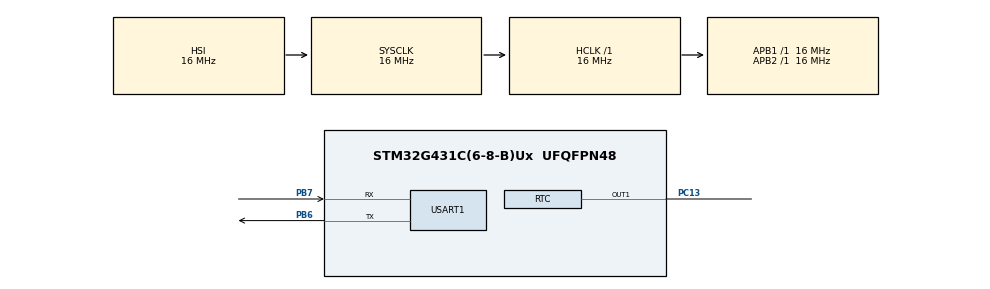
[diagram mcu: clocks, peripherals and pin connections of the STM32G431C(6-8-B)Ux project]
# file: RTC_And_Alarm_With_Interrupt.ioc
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Mcu.Family=STM32G4
Mcu.Name=STM32G431C(6-8-B)Ux
Mcu.Package=UFQFPN48
NVIC.PriorityGroup=NVIC_PRIORITYGROUP_4
NVIC.RTC_Alarm_IRQn=true\:0\:0\:false\:false\:true\:true\:true\:true
NVIC.RTC_WKUP_IRQn=true\:0\:0\:false\:false\:true\:true\:true\:true
PA13.Mode=Serial_Wire
PA13.Signal=SYS_JTMS-SWDIO
PA14.Mode=Serial_Wire
PA14.Signal=SYS_JTCK-SWCLK
PB6.Mode=Asynchronous
PB6.Signal=USART1_TX
PB7.Mode=Asynchronous
PB7.Signal=USART1_RX
PC13.Mode=WakeUpAF1
PC13.Signal=RTC_OUT1
PF0-OSC_IN.Mode=HSE-External-Oscillator
PF0-OSC_IN.Signal=RCC_OSC_IN
PF1-OSC_OUT.Mode=HSE-External-Oscillator
PF1-OSC_OUT.Signal=RCC_OSC_OUT
ProjectManager.HeapSize=0x200
ProjectManager.StackSize=0x400
ProjectManager.TargetToolchain=STM32CubeIDE
RCC.AHBFreq_Value=16000000
RCC.APB1Freq_Value=16000000
RCC.APB1TimFreq_Value=16000000
RCC.APB2Freq_Value=16000000
RCC.APB2TimFreq_Value=16000000
RCC.CortexFreq_Value=16000000
RCC.EXTERNAL_CLOCK_VALUE=12288000
RCC.HCLKFreq_Value=16000000
RCC.HSE_VALUE=8000000
RCC.HSI48_VALUE=48000000
RCC.HSI_VALUE=16000000
RCC.LSE_VALUE=32768
RCC.PLLSourceVirtual=RCC_PLLSOURCE_HSE
RCC.SYSCLKFreq_VALUE=16000000
RCC.USBFreq_Value=32000000
RCC.VCOOutputFreq_Value=64000000
RTC.Alarm-Alarm\ A=RTC_ALARM_A
RTC.AlarmMaskDateWeekDay-Alarm\ A=RTC_ALARMMASK_DATEWEEKDAY
RTC.Date=2
RTC.Format=RTC_FORMAT_BIN
RTC.Hours=10
RTC.Hours_A-Alarm\ A=10
RTC.Minutes=34
RTC.Minutes_A-Alarm\ A=34
RTC.Month=RTC_MONTH_JANUARY
RTC.Seconds_A-Alarm\ A=10
RTC.SynchPrediv=249
RTC.WakeUpClock-WakeUpAF1=RTC_WAKEUPCLOCK_CK_SPRE_16BITS
RTC.WakeUpCounter-WakeUpAF1=5
RTC.WeekDay=RTC_WEEKDAY_MONDAY
RTC.Year=0
USART1.VirtualMode-Asynchronous=VM_ASYNC
VP_RTC_VS_RTC_Activate.Mode=RTC_Enabled
VP_RTC_VS_RTC_Alarm_A_Intern.Mode=Alarm A
VP_RTC_VS_RTC_Calendar.Mode=RTC_Calendar
VP_SYS_VS_DBSignals.Mode=DisableDeadBatterySignals
board=custom

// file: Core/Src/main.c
/* USER CODE BEGIN Header */
/**
  ******************************************************************************
  * @file           : main.c
  * @brief          : Main program body
  ******************************************************************************
  * @attention
  *
  * Copyright (c) 2026 STMicroelectronics.
  * All rights reserved.
  *
  * This software is licensed under terms that can be found in the LICENSE file
  * in the root directory of this software component.
  * If no LICENSE file comes with this software, it is provided AS-IS.
  *
  ******************************************************************************
  */
/* USER CODE END Header */
#include "main.h"

/* USER CODE BEGIN Includes */
#include <stdio.h>
#include <string.h>
/* USER CODE END Includes */

RTC_HandleTypeDef hrtc;

UART_HandleTypeDef huart1;

/* USER CODE BEGIN PV */
RTC_TimeTypeDef sTime = {0};
RTC_DateTypeDef DateToUpdate = {0};

char trans_str[64] = {0,};
/* USER CODE END PV */

void SystemClock_Config(void);
static void MX_GPIO_Init(void);
static void MX_RTC_Init(void);
static void MX_USART1_UART_Init(void);

/* USER CODE BEGIN 0 */
void HAL_RTC_AlarmAEventCallback(RTC_HandleTypeDef *hrtc)
{
	snprintf(trans_str, 63, "Alarm_A\n");
	HAL_UART_Transmit(&huart1, (uint8_t*)trans_str, strlen(trans_str), 1000);
}

void HAL_RTCEx_WakeUpTimerEventCallback(RTC_HandleTypeDef *hrtc)
{
	snprintf(trans_str, 63, "WakeUp\n");
	HAL_UART_Transmit(&huart1, (uint8_t*)trans_str, strlen(trans_str), 1000);
}

/* USER CODE END 0 */

int main(void)
{

  /* MCU Configuration--------------------------------------------------------*/

  /* Reset of all peripherals, Initializes the Flash interface and the Systick. */
  HAL_Init();

  /* Configure the system clock */
  SystemClock_Config();

  /* Initialize all configured peripherals */
  MX_GPIO_Init();
  MX_RTC_Init();
  MX_USART1_UART_Init();

  /* Infinite loop */
  while (1)
  {

    /* USER CODE BEGIN 3 */
      HAL_RTC_GetTime(&hrtc, &sTime, RTC_FORMAT_BIN); // RTC_FORMAT_BIN , RTC_FORMAT_BCD
      snprintf(trans_str, 63, "Time %d:%d:%d\n", sTime.Hours, sTime.Minutes, sTime.Seconds);
      HAL_UART_Transmit(&huart1, (uint8_t*)trans_str, strlen(trans_str), 1000);

      HAL_RTC_GetDate(&hrtc, &DateToUpdate, RTC_FORMAT_BIN);
      snprintf(trans_str, 63, "Date %d-%d-20%d\n", DateToUpdate.Date, DateToUpdate.Month, DateToUpdate.Year);
      HAL_UART_Transmit(&huart1, (uint8_t*)trans_str, strlen(trans_str), 1000);

      uint32_t wu = HAL_RTCEx_GetWakeUpTimer(&hrtc);
      snprintf(trans_str, 63, "WakeUp %lu\n\n", wu);
      HAL_UART_Transmit(&huart1, (uint8_t*)trans_str, strlen(trans_str), 1000);

      HAL_Delay(1000);
  }
  /* USER CODE END 3 */
}

void SystemClock_Config(void)
{
  RCC_OscInitTypeDef RCC_OscInitStruct = {0};
  RCC_ClkInitTypeDef RCC_ClkInitStruct = {0};

  /** Configure the main internal regulator output voltage
  */
  HAL_PWREx_ControlVoltageScaling(PWR_REGULATOR_VOLTAGE_SCALE1);

  /** Initializes the RCC Oscillators according to the specified parameters
  * in the RCC_OscInitTypeDef structure.
  */
  RCC_OscInitStruct.OscillatorType = RCC_OSCILLATORTYPE_HSI|RCC_OSCILLATORTYPE_LSI;
  RCC_OscInitStruct.HSIState = RCC_HSI_ON;
  RCC_OscInitStruct.HSICalibrationValue = RCC_HSICALIBRATION_DEFAULT;
  RCC_OscInitStruct.LSIState = RCC_LSI_ON;
  RCC_OscInitStruct.PLL.PLLState = RCC_PLL_NONE;
  if (HAL_RCC_OscConfig(&RCC_OscInitStruct) != HAL_OK)
  {
    Error_Handler();
  }

  /** Initializes the CPU, AHB and APB buses clocks
  */
  RCC_ClkInitStruct.ClockType = RCC_CLOCKTYPE_HCLK|RCC_CLOCKTYPE_SYSCLK
                              |RCC_CLOCKTYPE_PCLK1|RCC_CLOCKTYPE_PCLK2;
  RCC_ClkInitStruct.SYSCLKSource = RCC_SYSCLKSOURCE_HSI;
  RCC_ClkInitStruct.AHBCLKDivider = RCC_SYSCLK_DIV1;
  RCC_ClkInitStruct.APB1CLKDivider = RCC_HCLK_DIV1;
  RCC_ClkInitStruct.APB2CLKDivider = RCC_HCLK_DIV1;

  if (HAL_RCC_ClockConfig(&RCC_ClkInitStruct, FLASH_LATENCY_0) != HAL_OK)
  {
    Error_Handler();
  }
}

static void MX_RTC_Init(void)
{

  RTC_TimeTypeDef sTime = {0};
  RTC_DateTypeDef sDate = {0};
  RTC_AlarmTypeDef sAlarm = {0};

  /** Initialize RTC Only
  */
  hrtc.Instance = RTC;
  hrtc.Init.HourFormat = RTC_HOURFORMAT_24;
  hrtc.Init.AsynchPrediv = 127;
  hrtc.Init.SynchPrediv = 249;
  hrtc.Init.OutPut = RTC_OUTPUT_WAKEUP;
  hrtc.Init.OutPutRemap = RTC_OUTPUT_REMAP_NONE;
  hrtc.Init.OutPutPolarity = RTC_OUTPUT_POLARITY_HIGH;
  hrtc.Init.OutPutType = RTC_OUTPUT_TYPE_OPENDRAIN;
  hrtc.Init.OutPutPullUp = RTC_OUTPUT_PULLUP_ON;
  if (HAL_RTC_Init(&hrtc) != HAL_OK)
  {
    Error_Handler();
  }

  /** Initialize RTC and set the Time and Date
  */
  sTime.Hours = 10;
  sTime.Minutes = 34;
  sTime.Seconds = 0;
  sTime.SubSeconds = 0;
  sTime.DayLightSaving = RTC_DAYLIGHTSAVING_NONE;
  sTime.StoreOperation = RTC_STOREOPERATION_RESET;
  if (HAL_RTC_SetTime(&hrtc, &sTime, RTC_FORMAT_BIN) != HAL_OK)
  {
    Error_Handler();
  }
  sDate.WeekDay = RTC_WEEKDAY_MONDAY;
  sDate.Month = RTC_MONTH_JANUARY;
  sDate.Date = 2;
  sDate.Year = 0;
  if (HAL_RTC_SetDate(&hrtc, &sDate, RTC_FORMAT_BIN) != HAL_OK)
  {
    Error_Handler();
  }

  /** Enable the Alarm A
  */
  sAlarm.AlarmTime.Hours = 10;
  sAlarm.AlarmTime.Minutes = 34;
  sAlarm.AlarmTime.Seconds = 10;
  sAlarm.AlarmTime.SubSeconds = 0;
  sAlarm.AlarmMask = RTC_ALARMMASK_DATEWEEKDAY;
  sAlarm.AlarmSubSecondMask = RTC_ALARMSUBSECONDMASK_ALL;
  sAlarm.AlarmDateWeekDaySel = RTC_ALARMDATEWEEKDAYSEL_DATE;
  sAlarm.AlarmDateWeekDay = 1;
  sAlarm.Alarm = RTC_ALARM_A;
  if (HAL_RTC_SetAlarm_IT(&hrtc, &sAlarm, RTC_FORMAT_BIN) != HAL_OK)
  {
    Error_Handler();
  }

  /** Enable the WakeUp
  */
  if (HAL_RTCEx_SetWakeUpTimer_IT(&hrtc, 5, RTC_WAKEUPCLOCK_CK_SPRE_16BITS) != HAL_OK)
  {
    Error_Handler();
  }

}

static void MX_USART1_UART_Init(void)
{

  huart1.Instance = USART1;
  huart1.Init.BaudRate = 115200;
  huart1.Init.WordLength = UART_WORDLENGTH_8B;
  huart1.Init.StopBits = UART_STOPBITS_1;
  huart1.Init.Parity = UART_PARITY_NONE;
  huart1.Init.Mode = UART_MODE_TX_RX;
  huart1.Init.HwFlowCtl = UART_HWCONTROL_NONE;
  huart1.Init.OverSampling = UART_OVERSAMPLING_16;
  huart1.Init.OneBitSampling = UART_ONE_BIT_SAMPLE_DISABLE;
  huart1.Init.ClockPrescaler = UART_PRESCALER_DIV1;
  huart1.AdvancedInit.AdvFeatureInit = UART_ADVFEATURE_NO_INIT;
  if (HAL_UART_Init(&huart1) != HAL_OK)
  {
    Error_Handler();
  }
  if (HAL_UARTEx_SetTxFifoThreshold(&huart1, UART_TXFIFO_THRESHOLD_1_8) != HAL_OK)
  {
    Error_Handler();
  }
  if (HAL_UARTEx_SetRxFifoThreshold(&huart1, UART_RXFIFO_THRESHOLD_1_8) != HAL_OK)
  {
    Error_Handler();
  }
  if (HAL_UARTEx_DisableFifoMode(&huart1) != HAL_OK)
  {
    Error_Handler();
  }

}

static void MX_GPIO_Init(void)
{

  /* GPIO Ports Clock Enable */
  __HAL_RCC_GPIOC_CLK_ENABLE();
  __HAL_RCC_GPIOF_CLK_ENABLE();
  __HAL_RCC_GPIOA_CLK_ENABLE();
  __HAL_RCC_GPIOB_CLK_ENABLE();

}

void Error_Handler(void)
{
  __disable_irq();
  while (1)
  {
  }
}
